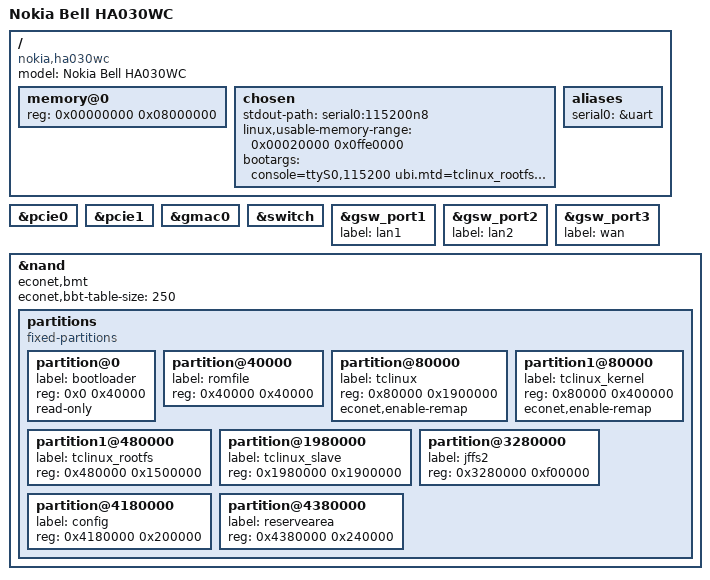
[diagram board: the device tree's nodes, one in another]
// SPDX-License-Identifier: GPL-2.0-or-later
//
// Nokia Bell HA030WC (中国移动定制)
// SoC: Econet EN7561DU (bootloader 报为 EN7528 家族, machine = econet,en751221)
// CPU: MIPS 1004Kc 多核, little-endian
// RAM: 128MB DDR3
// Flash: Winbond W25N01G 128MB SPI NAND
// WiFi: MT7603 (2.4G) + MT7663 (5G)
// Ports: 2x LAN + 1x WAN, 全千兆

/dts-v1/;
#include "en7528.dtsi"

/ {
	model = "Nokia Bell HA030WC";
	compatible = "nokia,ha030wc", "econet,en7528";

	memory@0 {
		device_type = "memory";
		reg = <0x00000000 0x08000000>;
	};

	chosen {
		stdout-path = "serial0:115200n8";
		linux,usable-memory-range = <0x00020000 0x0ffe0000>;
		bootargs = "console=ttyS0,115200 ubi.mtd=tclinux_rootfs root=ubi0:rootfs rootfstype=ubifs";
	};

	aliases {
		serial0 = &uart;
	};
};

&pcie0 { status = "okay"; };
&pcie1 { status = "okay"; };

&gmac0 { status = "okay"; };
&switch { status = "okay"; };

&gsw_port1 { label = "lan1"; status = "okay"; };
&gsw_port2 { label = "lan2"; status = "okay"; };
&gsw_port3 { label = "wan";  status = "okay"; };

&nand {
	status = "okay";
	econet,bmt;
	econet,bbt-table-size = <250>;

	partitions {
		compatible = "fixed-partitions";
		#address-cells = <1>;
		#size-cells = <1>;

		partition@0 {
			label = "bootloader";
			reg = <0x0 0x40000>;
			read-only;
		};

		partition@40000 {
			label = "romfile";
			reg = <0x40000 0x40000>;
		};

		partition@80000 {
			label = "tclinux";
			reg = <0x80000 0x1900000>;
			econet,enable-remap;
		};

		/* Nested: kernel (4MB) within tclinux */
		partition1@80000 {
			label = "tclinux_kernel";
			reg = <0x80000 0x400000>;
			econet,enable-remap;
		};

		/* Nested: UBI rootfs after kernel */
		partition1@480000 {
			label = "tclinux_rootfs";
			reg = <0x480000 0x1500000>;
		};

		partition@1980000 {
			label = "tclinux_slave";
			reg = <0x1980000 0x1900000>;
		};

		partition@3280000 {
			label = "jffs2";
			reg = <0x3280000 0xf00000>;
		};

		partition@4180000 {
			label = "config";
			reg = <0x4180000 0x200000>;
		};

		partition@4380000 {
			label = "reservearea";
			reg = <0x4380000 0x240000>;
		};
	};
};
